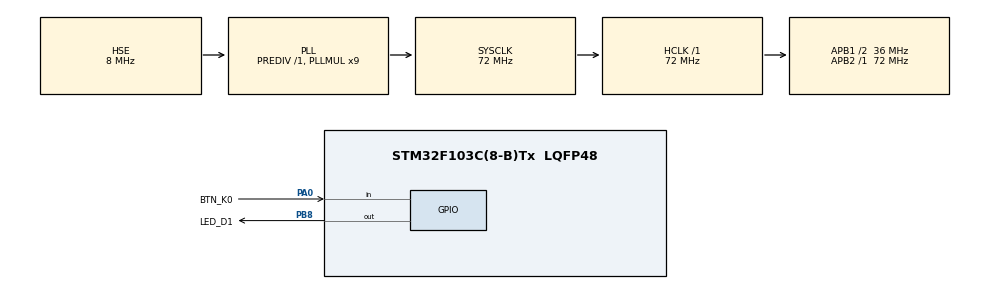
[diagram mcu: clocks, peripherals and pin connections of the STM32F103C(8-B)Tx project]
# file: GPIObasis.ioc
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Mcu.Family=STM32F1
Mcu.Name=STM32F103C(8-B)Tx
Mcu.Package=LQFP48
NVIC.PriorityGroup=NVIC_PRIORITYGROUP_4
PA0-WKUP.GPIO_Label=BTN_K0
PA0-WKUP.Signal=GPIO_Input
PA13.Mode=Serial_Wire
PA13.Signal=SYS_JTMS-SWDIO
PA14.Mode=Serial_Wire
PA14.Signal=SYS_JTCK-SWCLK
PB8.GPIO_Label=LED_D1
PB8.PinState=GPIO_PIN_SET
PB8.Signal=GPIO_Output
PD0-OSC_IN.Mode=HSE-External-Oscillator
PD0-OSC_IN.Signal=RCC_OSC_IN
PD1-OSC_OUT.Mode=HSE-External-Oscillator
PD1-OSC_OUT.Signal=RCC_OSC_OUT
ProjectManager.HeapSize=0x200
ProjectManager.StackSize=0x400
ProjectManager.TargetToolchain=STM32CubeIDE
RCC.AHBFreq_Value=72000000
RCC.APB1CLKDivider=RCC_HCLK_DIV2
RCC.APB1Freq_Value=36000000
RCC.APB1TimFreq_Value=72000000
RCC.APB2Freq_Value=72000000
RCC.APB2TimFreq_Value=72000000
RCC.HCLKFreq_Value=72000000
RCC.PLLMUL=RCC_PLL_MUL9
RCC.PLLSourceVirtual=RCC_PLLSOURCE_HSE
RCC.SYSCLKFreq_VALUE=72000000
RCC.SYSCLKSource=RCC_SYSCLKSOURCE_PLLCLK
RCC.USBFreq_Value=72000000
board=custom

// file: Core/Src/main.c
/* USER CODE BEGIN Header */
/**
  ******************************************************************************
  * @file           : main.c
  * @brief          : Main program body
  ******************************************************************************
  * @attention
  *
  * Copyright (c) 2023 STMicroelectronics.
  * All rights reserved.
  *
  * This software is licensed under terms that can be found in the LICENSE file
  * in the root directory of this software component.
  * If no LICENSE file comes with this software, it is provided AS-IS.
  *
  ******************************************************************************
  */
/* USER CODE END Header */
#include "main.h"

void SystemClock_Config(void);
static void MX_GPIO_Init(void);

/* USER CODE BEGIN 0 */
void delay_ms(volatile uint16_t delay)
{
	//Carefull!!! Timer 4 in only 16 bits!
	//TIM4->PSC = SystemCoreClock/1000000-1; //set Timer prescaler register
	//TIM4->PSC = (HAL_RCC_GetPCLK1Freq()*2)/1000000-1; //set Timer prescaler register
	TIM4->PSC = (HAL_RCC_GetPCLK1Freq())/1000000-1; //set Timer prescaler register
	TIM4->ARR = delay; //Set Timer Auto-reload register
	TIM4->EGR |= TIM_EGR_UG; // Set UG bit in EGR register to update upcounting mode
	TIM4->CR1 |= TIM_CR1_CEN|TIM_CR1_OPM; //Set one Pulse Mode (OPM) and enable the counter
	while((TIM4->CR1)&(TIM_CR1_CEN!=0)); //Check the counter enable bit - It clears automatically in one pulse mode
}
/* USER CODE END 0 */

int main(void)
{
  /* USER CODE BEGIN 1 */
	uint8_t btn_k0;
  /* USER CODE END 1 */

  /* MCU Configuration--------------------------------------------------------*/

  /* Reset of all peripherals, Initializes the Flash interface and the Systick. */
  HAL_Init();

  /* Configure the system clock */
  SystemClock_Config();

  /* Initialize all configured peripherals */
  MX_GPIO_Init();
  /* USER CODE BEGIN 2 */
  SET_BIT(RCC->APB1ENR, RCC_APB1ENR_TIM4EN); // Delay Timer Initialization
  /* USER CODE END 2 */

  /* Infinite loop */
  while (1)
  {

    /* USER CODE BEGIN 3 */
	  btn_k0 = HAL_GPIO_ReadPin(BTN_K0_GPIO_Port, BTN_K0_Pin); //Read Pin 4 status

	  	  if(btn_k0 == 0) //if switch K0 Pressed
	  	  {
	  		  HAL_GPIO_WritePin(LED_D1_GPIO_Port, LED_D1_Pin, GPIO_PIN_RESET); // Reset Pin 9 (Led On)
	  		  delay_ms(2000000);
	  		  HAL_GPIO_WritePin(LED_D1_GPIO_Port, LED_D1_Pin, GPIO_PIN_SET); // Set Pin 9 (Led Off)
	  	  }

  }
  /* USER CODE END 3 */
}

void SystemClock_Config(void)
{
  RCC_OscInitTypeDef RCC_OscInitStruct = {0};
  RCC_ClkInitTypeDef RCC_ClkInitStruct = {0};

  /** Initializes the RCC Oscillators according to the specified parameters
  * in the RCC_OscInitTypeDef structure.
  */
  RCC_OscInitStruct.OscillatorType = RCC_OSCILLATORTYPE_HSE;
  RCC_OscInitStruct.HSEState = RCC_HSE_ON;
  RCC_OscInitStruct.HSEPredivValue = RCC_HSE_PREDIV_DIV1;
  RCC_OscInitStruct.HSIState = RCC_HSI_ON;
  RCC_OscInitStruct.PLL.PLLState = RCC_PLL_ON;
  RCC_OscInitStruct.PLL.PLLSource = RCC_PLLSOURCE_HSE;
  RCC_OscInitStruct.PLL.PLLMUL = RCC_PLL_MUL9;
  if (HAL_RCC_OscConfig(&RCC_OscInitStruct) != HAL_OK)
  {
    Error_Handler();
  }

  /** Initializes the CPU, AHB and APB buses clocks
  */
  RCC_ClkInitStruct.ClockType = RCC_CLOCKTYPE_HCLK|RCC_CLOCKTYPE_SYSCLK
                              |RCC_CLOCKTYPE_PCLK1|RCC_CLOCKTYPE_PCLK2;
  RCC_ClkInitStruct.SYSCLKSource = RCC_SYSCLKSOURCE_PLLCLK;
  RCC_ClkInitStruct.AHBCLKDivider = RCC_SYSCLK_DIV1;
  RCC_ClkInitStruct.APB1CLKDivider = RCC_HCLK_DIV2;
  RCC_ClkInitStruct.APB2CLKDivider = RCC_HCLK_DIV1;

  if (HAL_RCC_ClockConfig(&RCC_ClkInitStruct, FLASH_LATENCY_2) != HAL_OK)
  {
    Error_Handler();
  }
}

static void MX_GPIO_Init(void)
{
  GPIO_InitTypeDef GPIO_InitStruct = {0};

  /* GPIO Ports Clock Enable */
  __HAL_RCC_GPIOD_CLK_ENABLE();
  __HAL_RCC_GPIOA_CLK_ENABLE();
  __HAL_RCC_GPIOB_CLK_ENABLE();

  /*Configure GPIO pin Output Level */
  HAL_GPIO_WritePin(LED_D1_GPIO_Port, LED_D1_Pin, GPIO_PIN_SET);

  /*Configure GPIO pin : BTN_K0_Pin */
  GPIO_InitStruct.Pin = BTN_K0_Pin;
  GPIO_InitStruct.Mode = GPIO_MODE_INPUT;
  GPIO_InitStruct.Pull = GPIO_NOPULL;
  HAL_GPIO_Init(BTN_K0_GPIO_Port, &GPIO_InitStruct);

  /*Configure GPIO pin : LED_D1_Pin */
  GPIO_InitStruct.Pin = LED_D1_Pin;
  GPIO_InitStruct.Mode = GPIO_MODE_OUTPUT_PP;
  GPIO_InitStruct.Pull = GPIO_NOPULL;
  GPIO_InitStruct.Speed = GPIO_SPEED_FREQ_LOW;
  HAL_GPIO_Init(LED_D1_GPIO_Port, &GPIO_InitStruct);

}

void Error_Handler(void)
{
  __disable_irq();
  while (1)
  {
  }
}
